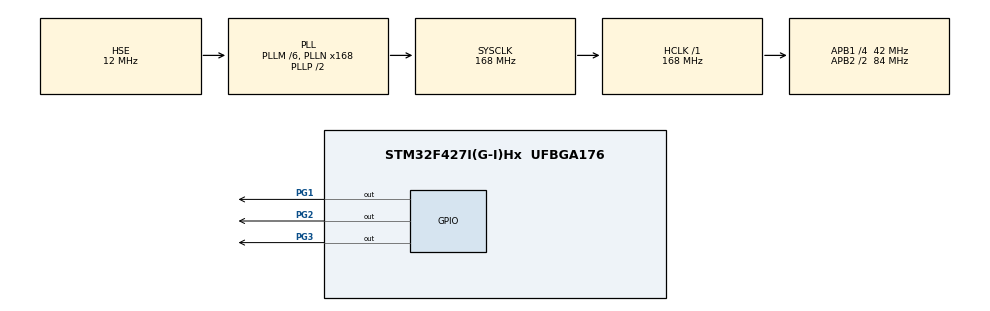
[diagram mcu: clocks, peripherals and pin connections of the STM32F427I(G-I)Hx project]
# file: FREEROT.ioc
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FREERTOS.Tasks01=defaultTask,0,128,StartDefaultTask,Default,NULL,Dynamic,NULL,NULL;myTask02,-3,128,StartTask02,Default,NULL,Dynamic,NULL,NULL;myTask03,-3,128,StartTask03,Default,NULL,Dynamic,NULL,NULL;myTask04,-3,128,StartTask04,Default,NULL,Dynamic,NULL,NULL
Mcu.Family=STM32F4
Mcu.Name=STM32F427I(G-I)Hx
Mcu.Package=UFBGA176
NVIC.PriorityGroup=NVIC_PRIORITYGROUP_4
NVIC.TIM2_IRQn=true\:0\:0\:false\:false\:true\:false\:false\:true
NVIC.TimeBase=TIM2_IRQn
NVIC.TimeBaseIP=TIM2
PG1.Signal=GPIO_Output
PG2.Signal=GPIO_Output
PG3.Signal=GPIO_Output
PH0/OSC_IN.Mode=HSE-External-Oscillator
PH0/OSC_IN.Signal=RCC_OSC_IN
PH1/OSC_OUT.Mode=HSE-External-Oscillator
PH1/OSC_OUT.Signal=RCC_OSC_OUT
ProjectManager.HeapSize=0x200
ProjectManager.StackSize=0x400
ProjectManager.TargetToolchain=MDK-ARM V5
RCC.48MHZClocksFreq_Value=84000000
RCC.AHBFreq_Value=168000000
RCC.APB1CLKDivider=RCC_HCLK_DIV4
RCC.APB1Freq_Value=42000000
RCC.APB1TimFreq_Value=84000000
RCC.APB2CLKDivider=RCC_HCLK_DIV2
RCC.APB2Freq_Value=84000000
RCC.APB2TimFreq_Value=168000000
RCC.CortexFreq_Value=168000000
RCC.HCLKFreq_Value=168000000
RCC.HSE_VALUE=12000000
RCC.HSI_VALUE=16000000
RCC.LSE_VALUE=32768
RCC.PLLM=6
RCC.PLLN=168
RCC.PLLSourceVirtual=RCC_PLLSOURCE_HSE
RCC.SYSCLKFreq_VALUE=168000000
RCC.SYSCLKSource=RCC_SYSCLKSOURCE_PLLCLK
RCC.VCOOutputFreq_Value=336000000
VP_FREERTOS_VS_CMSIS_V1.Mode=CMSIS_V1
VP_SYS_VS_tim2.Mode=TIM2
board=custom

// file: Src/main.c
/* USER CODE BEGIN Header */
/**
  ******************************************************************************
  * @file           : main.c
  * @brief          : Main program body
  ******************************************************************************
  * @attention
  *
  * <h2><center>&copy; Copyright (c) 2020 STMicroelectronics.
  * All rights reserved.</center></h2>
  *
  * This software component is licensed by ST under Ultimate Liberty license
  * SLA0044, the "License"; You may not use this file except in compliance with
  * the License. You may obtain a copy of the License at:
  *                             www.st.com/SLA0044
  *
  ******************************************************************************
  */
/* USER CODE END Header */

#include "main.h"
#include "cmsis_os.h"
#include "gpio.h"

void SystemClock_Config(void);
void MX_FREERTOS_Init(void);

int main(void)
{

  /* MCU Configuration--------------------------------------------------------*/

  /* Reset of all peripherals, Initializes the Flash interface and the Systick. */
  HAL_Init();

  /* Configure the system clock */
  SystemClock_Config();

  /* Initialize all configured peripherals */
  MX_GPIO_Init();

  /* Call init function for freertos objects (in freertos.c) */
  MX_FREERTOS_Init();

  /* Start scheduler */
  osKernelStart();

  /* We should never get here as control is now taken by the scheduler */

  /* Infinite loop */
  while (1)
  {

  }
}

void SystemClock_Config(void)
{
  RCC_OscInitTypeDef RCC_OscInitStruct = {0};
  RCC_ClkInitTypeDef RCC_ClkInitStruct = {0};

  /** Configure the main internal regulator output voltage
  */
  __HAL_RCC_PWR_CLK_ENABLE();
  __HAL_PWR_VOLTAGESCALING_CONFIG(PWR_REGULATOR_VOLTAGE_SCALE1);
  /** Initializes the CPU, AHB and APB busses clocks
  */
  RCC_OscInitStruct.OscillatorType = RCC_OSCILLATORTYPE_HSE;
  RCC_OscInitStruct.HSEState = RCC_HSE_ON;
  RCC_OscInitStruct.PLL.PLLState = RCC_PLL_ON;
  RCC_OscInitStruct.PLL.PLLSource = RCC_PLLSOURCE_HSE;
  RCC_OscInitStruct.PLL.PLLM = 6;
  RCC_OscInitStruct.PLL.PLLN = 168;
  RCC_OscInitStruct.PLL.PLLP = RCC_PLLP_DIV2;
  RCC_OscInitStruct.PLL.PLLQ = 4;
  if (HAL_RCC_OscConfig(&RCC_OscInitStruct) != HAL_OK)
  {
    Error_Handler();
  }
  /** Initializes the CPU, AHB and APB busses clocks
  */
  RCC_ClkInitStruct.ClockType = RCC_CLOCKTYPE_HCLK|RCC_CLOCKTYPE_SYSCLK
                              |RCC_CLOCKTYPE_PCLK1|RCC_CLOCKTYPE_PCLK2;
  RCC_ClkInitStruct.SYSCLKSource = RCC_SYSCLKSOURCE_PLLCLK;
  RCC_ClkInitStruct.AHBCLKDivider = RCC_SYSCLK_DIV1;
  RCC_ClkInitStruct.APB1CLKDivider = RCC_HCLK_DIV4;
  RCC_ClkInitStruct.APB2CLKDivider = RCC_HCLK_DIV2;

  if (HAL_RCC_ClockConfig(&RCC_ClkInitStruct, FLASH_LATENCY_5) != HAL_OK)
  {
    Error_Handler();
  }
}

void HAL_TIM_PeriodElapsedCallback(TIM_HandleTypeDef *htim)
{
  if (htim->Instance == TIM2) {
    HAL_IncTick();
  }
}

void Error_Handler(void)
{
}

/************************ (C) COPYRIGHT STMicroelectronics *****END OF FILE****/

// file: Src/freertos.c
/* USER CODE BEGIN Header */
/**
  ******************************************************************************
  * File Name          : freertos.c
  * Description        : Code for freertos applications
  ******************************************************************************
  * @attention
  *
  * <h2><center>&copy; Copyright (c) 2020 STMicroelectronics.
  * All rights reserved.</center></h2>
  *
  * This software component is licensed by ST under Ultimate Liberty license
  * SLA0044, the "License"; You may not use this file except in compliance with
  * the License. You may obtain a copy of the License at:
  *                             www.st.com/SLA0044
  *
  ******************************************************************************
  */
/* USER CODE END Header */

#include "FreeRTOS.h"
#include "task.h"
#include "main.h"
#include "cmsis_os.h"

osThreadId defaultTaskHandle;
osThreadId myTask02Handle;
osThreadId myTask03Handle;
osThreadId myTask04Handle;

void StartDefaultTask(void const * argument);
void StartTask02(void const * argument);
void StartTask03(void const * argument);
void StartTask04(void const * argument);

void MX_FREERTOS_Init(void); /* (MISRA C 2004 rule 8.1) */

/* GetIdleTaskMemory prototype (linked to static allocation support) */
void vApplicationGetIdleTaskMemory( StaticTask_t **ppxIdleTaskTCBBuffer, StackType_t **ppxIdleTaskStackBuffer, uint32_t *pulIdleTaskStackSize );

/* USER CODE BEGIN GET_IDLE_TASK_MEMORY */
static StaticTask_t xIdleTaskTCBBuffer;
static StackType_t xIdleStack[configMINIMAL_STACK_SIZE];

void vApplicationGetIdleTaskMemory( StaticTask_t **ppxIdleTaskTCBBuffer, StackType_t **ppxIdleTaskStackBuffer, uint32_t *pulIdleTaskStackSize )
{
  *ppxIdleTaskTCBBuffer = &xIdleTaskTCBBuffer;
  *ppxIdleTaskStackBuffer = &xIdleStack[0];
  *pulIdleTaskStackSize = configMINIMAL_STACK_SIZE;
  /* place for user code */
}
/* USER CODE END GET_IDLE_TASK_MEMORY */

void MX_FREERTOS_Init(void) {

  /* Create the thread(s) */
  /* definition and creation of defaultTask */
  osThreadDef(defaultTask, StartDefaultTask, osPriorityNormal, 0, 128);
  defaultTaskHandle = osThreadCreate(osThread(defaultTask), NULL);

  /* definition and creation of myTask02 */
  osThreadDef(myTask02, StartTask02, osPriorityIdle, 0, 128);
  myTask02Handle = osThreadCreate(osThread(myTask02), NULL);

  /* definition and creation of myTask03 */
  osThreadDef(myTask03, StartTask03, osPriorityIdle, 0, 128);
  myTask03Handle = osThreadCreate(osThread(myTask03), NULL);

  /* definition and creation of myTask04 */
  osThreadDef(myTask04, StartTask04, osPriorityIdle, 0, 128);
  myTask04Handle = osThreadCreate(osThread(myTask04), NULL);

}

void StartDefaultTask(void const * argument)
{

  for(;;)
  {
    osDelay(1);
  }
}

void StartTask02(void const * argument)
{
  /* USER CODE BEGIN StartTask02 */
  /* Infinite loop */
  for(;;)
  {
		HAL_GPIO_WritePin(GPIOG,GPIO_PIN_1,GPIO_PIN_SET);
    osDelay(500);
		HAL_GPIO_WritePin(GPIOG,GPIO_PIN_1,GPIO_PIN_RESET);
    osDelay(500);
  }
  /* USER CODE END StartTask02 */
}

void StartTask03(void const * argument)
{
  /* USER CODE BEGIN StartTask03 */
  /* Infinite loop */
  for(;;)
  {
    HAL_GPIO_WritePin(GPIOG,GPIO_PIN_2,GPIO_PIN_SET);
    osDelay(500);
		HAL_GPIO_WritePin(GPIOG,GPIO_PIN_2,GPIO_PIN_RESET);
    osDelay(500);
  }
  /* USER CODE END StartTask03 */
}

void StartTask04(void const * argument)
{
  /* USER CODE BEGIN StartTask04 */
  /* Infinite loop */
  for(;;)
  {
    HAL_GPIO_WritePin(GPIOG,GPIO_PIN_3,GPIO_PIN_SET);
    osDelay(500);
		HAL_GPIO_WritePin(GPIOG,GPIO_PIN_3,GPIO_PIN_RESET);
    osDelay(500);
  }
  /* USER CODE END StartTask04 */
}

/************************ (C) COPYRIGHT STMicroelectronics *****END OF FILE****/
